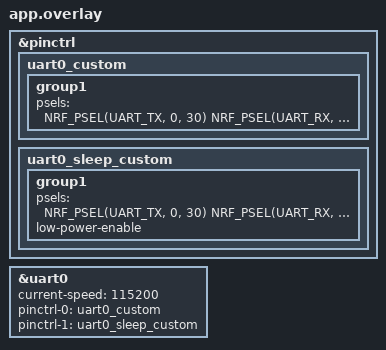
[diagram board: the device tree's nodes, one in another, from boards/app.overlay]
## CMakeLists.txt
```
cmake_minimum_required(VERSION 3.20.0)
find_package(Zephyr REQUIRED HINTS $ENV{ZEPHYR_BASE})

project(fth_uart1_rx_test)

target_sources(app PRIVATE 
    src/main.c
    src/uart_comm.c
)
```

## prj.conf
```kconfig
CONFIG_SERIAL=y
CONFIG_UART_INTERRUPT_DRIVEN=n

CONFIG_CLOCK_CONTROL_NRF_K32SRC_RC=n
CONFIG_CLOCK_CONTROL_NRF_K32SRC_XTAL=y
```

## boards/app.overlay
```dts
&pinctrl {
    uart0_custom: uart0_custom {
        group1 {
            psels = <
                NRF_PSEL(UART_TX, 0, 30)
                NRF_PSEL(UART_RX, 0, 31)
            >;
        };
    };

    uart0_sleep_custom: uart0_sleep_custom {
        group1 {
            psels = <
                NRF_PSEL(UART_TX, 0, 30)
                NRF_PSEL(UART_RX, 0, 31)
            >;
            low-power-enable;
        };
    };
};

&uart0 {
    status = "okay";
    current-speed = <115200>;

    pinctrl-0 = <&uart0_custom>;
    pinctrl-1 = <&uart0_sleep_custom>;
    pinctrl-names = "default", "sleep";
};
```

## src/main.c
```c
#include <zephyr/kernel.h>
#include "uart_comm.h"

/*
counter her saniye artar.
Her saniye UART'a yazdırılır.
Eğer kullanıcı veri gönderirse, gelen satır işlenir.
Veri gelmesini beklerken program bloke olmamalı.

Beklenen çıktı:

Counter: 1
Counter: 2
Counter: 3
Counter: 4

Kullanıcı yazarsa:

hello
Aldim: hello

sonra tekrar:

Counter: 5
Counter: 6
Counter: 7
...
*/

#define RX_LINE_SIZE 64

int main(void)
{
    char line[RX_LINE_SIZE];
    uint32_t counter = 0;

    if (uart_comm_init() != 0) {
        return 0;
    }

    uart_comm_send_str("Basladi\r\n");

    while (1)
    {
        int len = uart_comm_read_line(line,
                                      sizeof(line),
                                      1000);   // 1 saniye bekle

        if (len > 0)
        {
            uart_comm_send_str("Aldim: ");
            uart_comm_send_str(line);
            uart_comm_send_str("\r\n");
        }
        else
        {
            counter++;

            char msg[32];
            snprintf(msg,
                     sizeof(msg),
                     "Counter: %lu\r\n",
                     (unsigned long)counter);

            uart_comm_send_str(msg);
        }
    }
}


/*

karakter karakter değil satır tamamlanınca 

hello
Aldim: hello

fth
Aldim: fth gibi

#include <zephyr/kernel.h>
#include "uart_comm.h"

#define RX_LINE_SIZE 64

int main(void)
{
    char line[RX_LINE_SIZE];

    if (uart_comm_init() != 0) {
        return 0;
    }

    uart_comm_send_str("\r\nUART moduler test basladi\r\n");
    uart_comm_send_str("Bir metin yazip Enter'a basin.\r\n");

    while (1) {
        int len = uart_comm_read_line(line, sizeof(line), -1);

        if (len > 0) {
            uart_comm_send_str("Aldim: ");
            uart_comm_send_str(line);
            uart_comm_send_str("\r\n");
        } else if (len == -2) {
            uart_comm_send_str("Hata: satir buffer doldu\r\n");
        }
    }
}*/

/*
tek tek alma testi

hello
[h]
[e]
[l]
[l]
[o]
[
]


#include <zephyr/kernel.h>
#include <zephyr/device.h>
#include <zephyr/drivers/uart.h>

#define UART_NODE DT_NODELABEL(uart0)

static const struct device *uart_dev = DEVICE_DT_GET(UART_NODE);

int main(void)
{
    uint8_t ch;

    if (!device_is_ready(uart_dev)) {
        return 0;
    }

    while (1) {

        if (uart_poll_in(uart_dev, &ch) == 0) {

            uart_poll_out(uart_dev, '[');
            uart_poll_out(uart_dev, ch);
            uart_poll_out(uart_dev, ']');
            uart_poll_out(uart_dev, '\r');
            uart_poll_out(uart_dev, '\n');
        }

        k_msleep(10);
    }
}*/
```

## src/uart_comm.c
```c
#include "uart_comm.h"

#include <zephyr/kernel.h>
#include <zephyr/device.h>
#include <zephyr/drivers/uart.h>

#define UART_NODE DT_NODELABEL(uart0)

static const struct device *uart_dev = DEVICE_DT_GET(UART_NODE);

int uart_comm_init(void)
{
    if (!device_is_ready(uart_dev)) {
        return -1;
    }

    return 0;
}

void uart_comm_send_char(char c)
{
    uart_poll_out(uart_dev, c);
}

void uart_comm_send_str(const char *str)
{
    while (*str) {
        uart_poll_out(uart_dev, *str++);
    }
}

int uart_comm_read_char(uint8_t *ch)
{
    return uart_poll_in(uart_dev, ch);
}

int uart_comm_read_line(char *buf, size_t buf_size, int32_t timeout_ms)
{
    uint8_t ch;
    size_t pos = 0;
    int64_t start = k_uptime_get();

    if (buf == NULL || buf_size == 0) {
        return -1;
    }

    while (1) {
        if (uart_poll_in(uart_dev, &ch) == 0) {

            if (ch == '\r' || ch == '\n') {
                if (pos > 0) {
                    buf[pos] = '\0';
                    return (int)pos;
                }
            } else {
                if (pos < buf_size - 1) {
                    buf[pos++] = (char)ch;
                } else {
                    buf[pos] = '\0';
                    return -2;
                }
            }
        }

        if (timeout_ms >= 0) {
            if ((k_uptime_get() - start) >= timeout_ms) {
                buf[pos] = '\0';
                return 0;
            }
        }

        k_msleep(2);
    }
}
```

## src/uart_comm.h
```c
#ifndef UART_COMM_H
#define UART_COMM_H

#include <stdint.h>
#include <stddef.h>

int uart_comm_init(void);
void uart_comm_send_char(char c);
void uart_comm_send_str(const char *str);
int uart_comm_read_char(uint8_t *ch);
int uart_comm_read_line(char *buf, size_t buf_size, int32_t timeout_ms);

#endif
```
